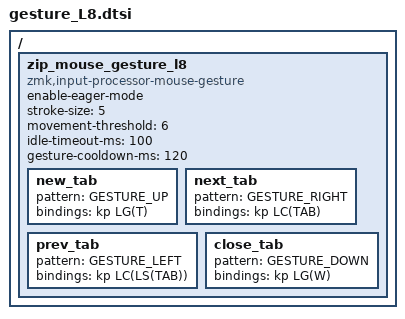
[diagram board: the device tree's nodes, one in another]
/ {
    zip_mouse_gesture_l8: zip_mouse_gesture_l8 {
        compatible = "zmk,input-processor-mouse-gesture";
        #input-processor-cells = <0>;
        enable-eager-mode;
        stroke-size = <5>;
        movement-threshold = <6>;
        idle-timeout-ms = <100>;
        gesture-cooldown-ms = <120>;

        new_tab   { pattern = <GESTURE_UP>;    bindings = <&kp LG(T)>; };       // Cmd+T
        next_tab  { pattern = <GESTURE_RIGHT>; bindings = <&kp LC(TAB)>; };      // Ctrl+Tab
        prev_tab  { pattern = <GESTURE_LEFT>;  bindings = <&kp LC(LS(TAB))>; };  // Ctrl+Shift+Tab
        close_tab { pattern = <GESTURE_DOWN>;  bindings = <&kp LG(W)>; };        // Cmd+W
    };
};
